# CBASS_RT_CFG0_ISC register map
Vendor: Texas Instruments
Peripheral module from a debugger description file (folder J722S).
Registers are 32-bit, read-write, reset 0x0 unless marked. A register's access mark holds for its fields unless they carry their own. Offsets are as the file gives them; lines under a group give offsets from that group; [hi:lo] are bit positions; {n}, {i} and the like mark numbered series; 'fields as' and 'values as' point back to an identical list; <NAME> marks a mode.

## CBASS_RT_CFG0_ISC
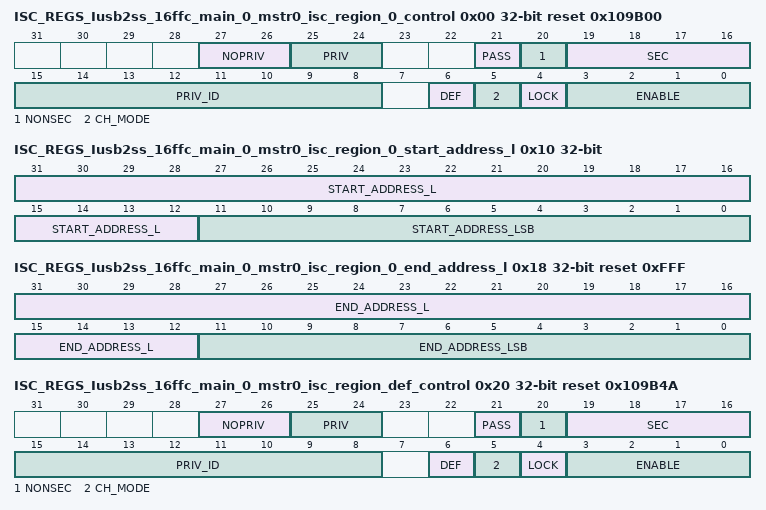
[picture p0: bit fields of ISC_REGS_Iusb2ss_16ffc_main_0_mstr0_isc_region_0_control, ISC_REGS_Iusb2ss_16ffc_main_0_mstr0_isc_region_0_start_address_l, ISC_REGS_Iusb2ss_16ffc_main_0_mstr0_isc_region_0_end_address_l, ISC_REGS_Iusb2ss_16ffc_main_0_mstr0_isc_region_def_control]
0x00 ISC_REGS_Iusb2ss_16ffc_main_0_mstr0_isc_region_0_control access not given reset 0x109B00 — The ISC Region 0 Control Register defines the control fields for the initiator Iusb2ss_16ffc_main_0.mstr0 region 0 ISC.
  [27:26] NOPRIV rw — Clear output priv attribute. If each bit is set then the outgoing priv bit is cleared.
  [25:24] PRIV rw — Set outgoing priv attribute. If each bit is set then the outgoing priv bit is set.
  [21] PASS rw — No privID replacement, pass through value.
  [20] NONSEC rw — Make outgoing non-secure.
  [19:16] SEC rw — Make outgoing secure. A value of 0xA enables, others disable.
  [15:8] PRIV_ID rw
  [6] DEF ro — Default region indication. The default region is used when all other regions do not match.
  [5] CH_MODE rw — Enable channel mode to match region to a chanid value. Otherwise use address mode to match region to an address range.
  [4] LOCK — Lock region. Once set the region values cannot be modified. (access R/W1TS)
  [3:0] ENABLE rw — Enable region. A value of 0xA enables, others disable.
0x10 ISC_REGS_Iusb2ss_16ffc_main_0_mstr0_isc_region_0_start_address_l — The ISC Region 0 Start Address Low Register defines the start address bits 31 to 0 for the initiator Iusb2ss_16ffc_main_0.mstr0 region 0 ISC.
  [31:12] START_ADDRESS_L — Start address bits 31 to 12.
  [11:0] START_ADDRESS_LSB — Start address bits 11 to 0 must be 0 as address must be 4KB aligned in address mode. Can also be channel number in channel mode.
0x14 ISC_REGS_Iusb2ss_16ffc_main_0_mstr0_isc_region_0_start_address_h — The ISC Region 0 Start Address High Register defines the start address bits 47 to 32 for the initiator Iusb2ss_16ffc_main_0.mstr0 region 0 ISC.
  [15:0] START_ADDRESS_H — Start address bits 47 to 32.
0x18 ISC_REGS_Iusb2ss_16ffc_main_0_mstr0_isc_region_0_end_address_l access per field reset 0xFFF — The ISC Region 0 End Address Low Register defines the end included address bits 31 to 0 for the initiator Iusb2ss_16ffc_main_0.mstr0 region 0 ISC.
  [31:12] END_ADDRESS_L rw — End address bits 31 to 12 to include in the match.
  [11:0] END_ADDRESS_LSB ro — End address bits 11 to 0 are forced to Fs as address must be 4KB aligned.
0x1C ISC_REGS_Iusb2ss_16ffc_main_0_mstr0_isc_region_0_end_address_h — The ISC Region 0 End Address High Register defines the end address bits 47 to 32 for the initiator Iusb2ss_16ffc_main_0.mstr0 region 0 ISC.
  [15:0] END_ADDRESS_H — End address bits 47 to 32.
0x20 ISC_REGS_Iusb2ss_16ffc_main_0_mstr0_isc_region_def_control access not given reset 0x109B4A — The ISC Default Region Control Register defines the control fields for the initiator Iusb2ss_16ffc_main_0.mstr0 region 1 ISC.
  [27:26] NOPRIV rw — Clear output priv attribute. If each bit is set then the outgoing priv bit is cleared, else the bit is unchanged. Do not set both priv and nopriv for the same bit.
  [25:24] PRIV rw — Set outgoing priv attribute. If each bit is set then the outgoing priv bit is set, else the bit is unchanged. Do not set both priv and nopriv for the same bit.
  [21] PASS rw — No privID replacement. A value of 1 will pass through privid value. A value of 0 will replace privid with priv_id field value.
  [20] NONSEC rw — Make outgoing non-secure. A value of 1 forces secure clear, others do nothing. Do not set both sec and nonsec.
  [19:16] SEC rw — Make outgoing secure. A value of 0xA forces secure set, others do nothing. Do not set both sec and nonsec.
  [15:8] PRIV_ID rw — Priv ID value to use if pass is 0.
  [6] DEF ro — Default region indication. The default region is used when all other regions do not match.
  [5] CH_MODE ro — Enable channel mode to match region to a chanid value. Otherwise use address mode to match region to an address range.
  [4] LOCK — Lock region. Once set, the region values cannot be modified. (access R/W1TS)
  [3:0] ENABLE ro — Enable region. A value of 0xA enables, others disable.
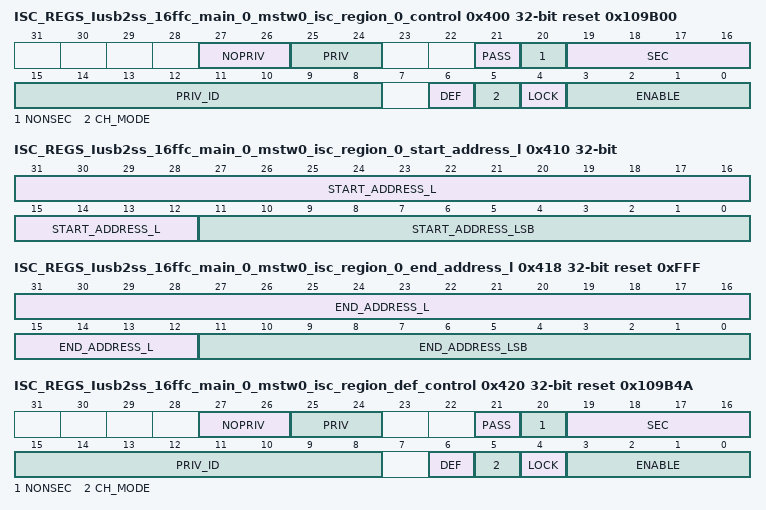
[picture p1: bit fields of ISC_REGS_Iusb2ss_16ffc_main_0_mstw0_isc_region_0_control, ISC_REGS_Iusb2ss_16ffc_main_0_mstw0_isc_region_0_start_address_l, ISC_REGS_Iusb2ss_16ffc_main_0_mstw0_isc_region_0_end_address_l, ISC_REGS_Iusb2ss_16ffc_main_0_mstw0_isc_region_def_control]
0x400 ISC_REGS_Iusb2ss_16ffc_main_0_mstw0_isc_region_0_control access not given reset 0x109B00 — The ISC Region 0 Control Register defines the control fields for the initiator Iusb2ss_16ffc_main_0.mstw0 region 0 ISC.
  fields as ISC_REGS_Iusb2ss_16ffc_main_0_mstr0_isc_region_0_control
0x410 ISC_REGS_Iusb2ss_16ffc_main_0_mstw0_isc_region_0_start_address_l — The ISC Region 0 Start Address Low Register defines the start address bits 31 to 0 for the initiator Iusb2ss_16ffc_main_0.mstw0 region 0 ISC.
  fields as ISC_REGS_Iusb2ss_16ffc_main_0_mstr0_isc_region_0_start_address_l
0x414 ISC_REGS_Iusb2ss_16ffc_main_0_mstw0_isc_region_0_start_address_h — The ISC Region 0 Start Address High Register defines the start address bits 47 to 32 for the initiator Iusb2ss_16ffc_main_0.mstw0 region 0 ISC.
  [15:0] START_ADDRESS_H — Start address bits 47 to 32.
0x418 ISC_REGS_Iusb2ss_16ffc_main_0_mstw0_isc_region_0_end_address_l access per field reset 0xFFF — The ISC Region 0 End Address Low Register defines the end included address bits 31 to 0 for the initiator Iusb2ss_16ffc_main_0.mstw0 region 0 ISC.
  fields as ISC_REGS_Iusb2ss_16ffc_main_0_mstr0_isc_region_0_end_address_l
0x41C ISC_REGS_Iusb2ss_16ffc_main_0_mstw0_isc_region_0_end_address_h — The ISC Region 0 End Address High Register defines the end address bits 47 to 32 for the initiator Iusb2ss_16ffc_main_0.mstw0 region 0 ISC.
  [15:0] END_ADDRESS_H — End address bits 47 to 32.
0x420 ISC_REGS_Iusb2ss_16ffc_main_0_mstw0_isc_region_def_control access not given reset 0x109B4A — The ISC Default Region Control Register defines the control fields for the initiator Iusb2ss_16ffc_main_0.mstw0 region 1 ISC.
  fields as ISC_REGS_Iusb2ss_16ffc_main_0_mstr0_isc_region_def_control
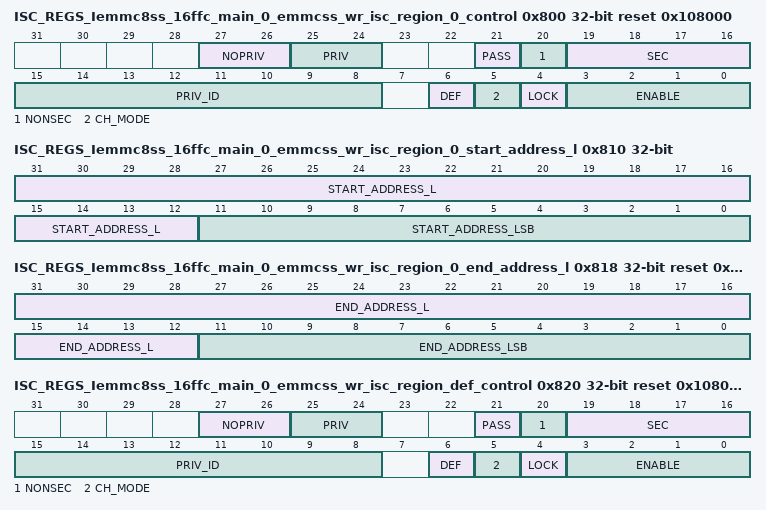
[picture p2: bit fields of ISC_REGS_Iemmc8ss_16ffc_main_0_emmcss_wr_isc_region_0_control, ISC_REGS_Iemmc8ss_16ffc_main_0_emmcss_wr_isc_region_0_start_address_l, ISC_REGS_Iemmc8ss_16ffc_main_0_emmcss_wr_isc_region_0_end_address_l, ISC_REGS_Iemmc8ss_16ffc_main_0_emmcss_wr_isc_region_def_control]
0x800 ISC_REGS_Iemmc8ss_16ffc_main_0_emmcss_wr_isc_region_0_control access not given reset 0x108000 — The ISC Region 0 Control Register defines the control fields for the initiator Iemmc8ss_16ffc_main_0.emmcss_wr region 0 ISC.
  fields as ISC_REGS_Iusb2ss_16ffc_main_0_mstr0_isc_region_0_control
0x810 ISC_REGS_Iemmc8ss_16ffc_main_0_emmcss_wr_isc_region_0_start_address_l — The ISC Region 0 Start Address Low Register defines the start address bits 31 to 0 for the initiator Iemmc8ss_16ffc_main_0.emmcss_wr region 0 ISC.
  fields as ISC_REGS_Iusb2ss_16ffc_main_0_mstr0_isc_region_0_start_address_l
0x814 ISC_REGS_Iemmc8ss_16ffc_main_0_emmcss_wr_isc_region_0_start_address_h — The ISC Region 0 Start Address High Register defines the start address bits 47 to 32 for the initiator Iemmc8ss_16ffc_main_0.emmcss_wr region 0 ISC.
  [15:0] START_ADDRESS_H — Start address bits 47 to 32.
0x818 ISC_REGS_Iemmc8ss_16ffc_main_0_emmcss_wr_isc_region_0_end_address_l access per field reset 0xFFF — The ISC Region 0 End Address Low Register defines the end included address bits 31 to 0 for the initiator Iemmc8ss_16ffc_main_0.emmcss_wr region 0 ISC.
  fields as ISC_REGS_Iusb2ss_16ffc_main_0_mstr0_isc_region_0_end_address_l
0x81C ISC_REGS_Iemmc8ss_16ffc_main_0_emmcss_wr_isc_region_0_end_address_h — The ISC Region 0 End Address High Register defines the end address bits 47 to 32 for the initiator Iemmc8ss_16ffc_main_0.emmcss_wr region 0 ISC.
  [15:0] END_ADDRESS_H — End address bits 47 to 32.
0x820 ISC_REGS_Iemmc8ss_16ffc_main_0_emmcss_wr_isc_region_def_control access not given reset 0x10804A — The ISC Default Region Control Register defines the control fields for the initiator Iemmc8ss_16ffc_main_0.emmcss_wr region 1 ISC.
  fields as ISC_REGS_Iusb2ss_16ffc_main_0_mstr0_isc_region_def_control
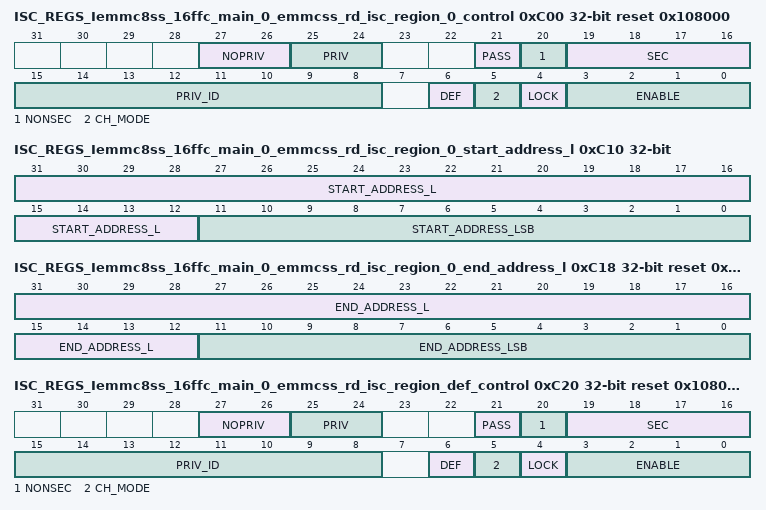
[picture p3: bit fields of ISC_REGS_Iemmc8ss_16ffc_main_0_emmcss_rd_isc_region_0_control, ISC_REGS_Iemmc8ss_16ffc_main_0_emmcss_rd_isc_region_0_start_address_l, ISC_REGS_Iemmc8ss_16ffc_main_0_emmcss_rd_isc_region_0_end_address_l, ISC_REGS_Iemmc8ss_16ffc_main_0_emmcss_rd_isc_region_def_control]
0xC00 ISC_REGS_Iemmc8ss_16ffc_main_0_emmcss_rd_isc_region_0_control access not given reset 0x108000 — The ISC Region 0 Control Register defines the control fields for the initiator Iemmc8ss_16ffc_main_0.emmcss_rd region 0 ISC.
  fields as ISC_REGS_Iusb2ss_16ffc_main_0_mstr0_isc_region_0_control
0xC10 ISC_REGS_Iemmc8ss_16ffc_main_0_emmcss_rd_isc_region_0_start_address_l — The ISC Region 0 Start Address Low Register defines the start address bits 31 to 0 for the initiator Iemmc8ss_16ffc_main_0.emmcss_rd region 0 ISC.
  fields as ISC_REGS_Iusb2ss_16ffc_main_0_mstr0_isc_region_0_start_address_l
0xC14 ISC_REGS_Iemmc8ss_16ffc_main_0_emmcss_rd_isc_region_0_start_address_h — The ISC Region 0 Start Address High Register defines the start address bits 47 to 32 for the initiator Iemmc8ss_16ffc_main_0.emmcss_rd region 0 ISC.
  [15:0] START_ADDRESS_H — Start address bits 47 to 32.
0xC18 ISC_REGS_Iemmc8ss_16ffc_main_0_emmcss_rd_isc_region_0_end_address_l access per field reset 0xFFF — The ISC Region 0 End Address Low Register defines the end included address bits 31 to 0 for the initiator Iemmc8ss_16ffc_main_0.emmcss_rd region 0 ISC.
  fields as ISC_REGS_Iusb2ss_16ffc_main_0_mstr0_isc_region_0_end_address_l
0xC1C ISC_REGS_Iemmc8ss_16ffc_main_0_emmcss_rd_isc_region_0_end_address_h — The ISC Region 0 End Address High Register defines the end address bits 47 to 32 for the initiator Iemmc8ss_16ffc_main_0.emmcss_rd region 0 ISC.
  [15:0] END_ADDRESS_H — End address bits 47 to 32.
0xC20 ISC_REGS_Iemmc8ss_16ffc_main_0_emmcss_rd_isc_region_def_control access not given reset 0x10804A — The ISC Default Region Control Register defines the control fields for the initiator Iemmc8ss_16ffc_main_0.emmcss_rd region 1 ISC.
  fields as ISC_REGS_Iusb2ss_16ffc_main_0_mstr0_isc_region_def_control
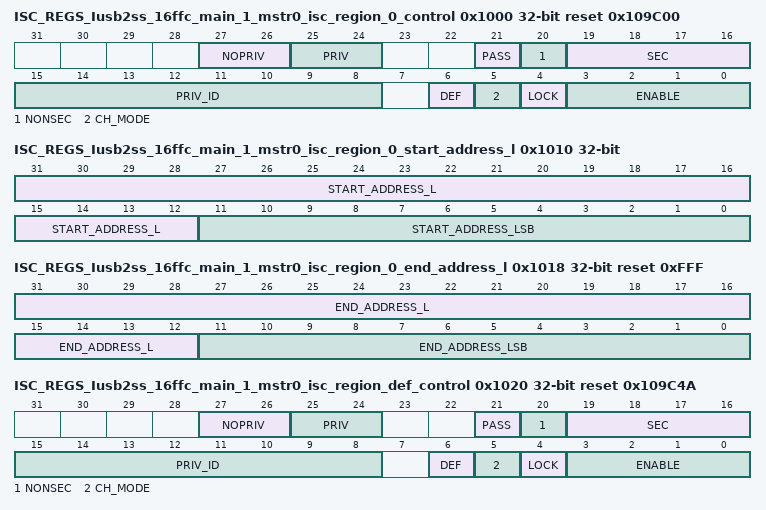
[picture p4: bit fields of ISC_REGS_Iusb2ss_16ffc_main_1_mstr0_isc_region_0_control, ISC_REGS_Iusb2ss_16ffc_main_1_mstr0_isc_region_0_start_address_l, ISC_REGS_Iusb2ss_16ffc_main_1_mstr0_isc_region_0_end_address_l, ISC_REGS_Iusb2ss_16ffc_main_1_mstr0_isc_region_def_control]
0x1000 ISC_REGS_Iusb2ss_16ffc_main_1_mstr0_isc_region_0_control access not given reset 0x109C00 — The ISC Region 0 Control Register defines the control fields for the initiator Iusb2ss_16ffc_main_1.mstr0 region 0 ISC.
  fields as ISC_REGS_Iusb2ss_16ffc_main_0_mstr0_isc_region_0_control
0x1010 ISC_REGS_Iusb2ss_16ffc_main_1_mstr0_isc_region_0_start_address_l — The ISC Region 0 Start Address Low Register defines the start address bits 31 to 0 for the initiator Iusb2ss_16ffc_main_1.mstr0 region 0 ISC.
  fields as ISC_REGS_Iusb2ss_16ffc_main_0_mstr0_isc_region_0_start_address_l
0x1014 ISC_REGS_Iusb2ss_16ffc_main_1_mstr0_isc_region_0_start_address_h — The ISC Region 0 Start Address High Register defines the start address bits 47 to 32 for the initiator Iusb2ss_16ffc_main_1.mstr0 region 0 ISC.
  [15:0] START_ADDRESS_H — Start address bits 47 to 32.
0x1018 ISC_REGS_Iusb2ss_16ffc_main_1_mstr0_isc_region_0_end_address_l access per field reset 0xFFF — The ISC Region 0 End Address Low Register defines the end included address bits 31 to 0 for the initiator Iusb2ss_16ffc_main_1.mstr0 region 0 ISC.
  fields as ISC_REGS_Iusb2ss_16ffc_main_0_mstr0_isc_region_0_end_address_l
0x101C ISC_REGS_Iusb2ss_16ffc_main_1_mstr0_isc_region_0_end_address_h — The ISC Region 0 End Address High Register defines the end address bits 47 to 32 for the initiator Iusb2ss_16ffc_main_1.mstr0 region 0 ISC.
  [15:0] END_ADDRESS_H — End address bits 47 to 32.
0x1020 ISC_REGS_Iusb2ss_16ffc_main_1_mstr0_isc_region_def_control access not given reset 0x109C4A — The ISC Default Region Control Register defines the control fields for the initiator Iusb2ss_16ffc_main_1.mstr0 region 1 ISC.
  fields as ISC_REGS_Iusb2ss_16ffc_main_0_mstr0_isc_region_def_control
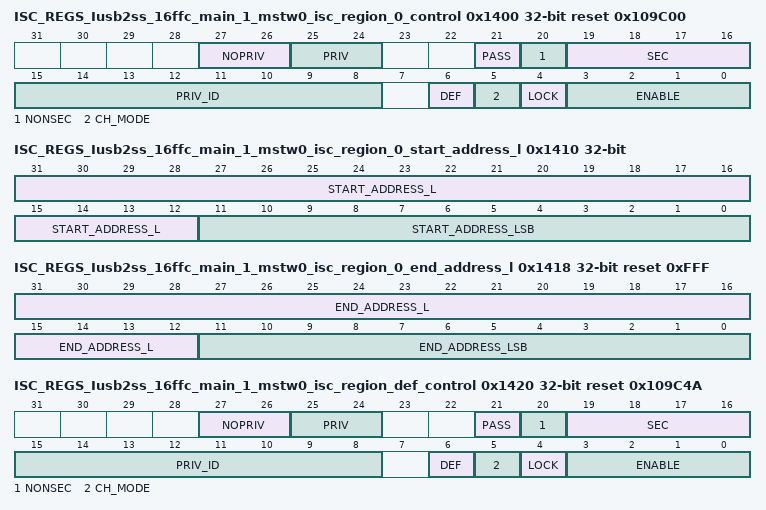
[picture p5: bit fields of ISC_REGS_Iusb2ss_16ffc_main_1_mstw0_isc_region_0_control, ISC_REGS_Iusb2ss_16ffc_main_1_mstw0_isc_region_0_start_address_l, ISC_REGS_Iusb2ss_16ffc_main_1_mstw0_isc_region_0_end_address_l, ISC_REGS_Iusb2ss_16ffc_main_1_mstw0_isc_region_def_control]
0x1400 ISC_REGS_Iusb2ss_16ffc_main_1_mstw0_isc_region_0_control access not given reset 0x109C00 — The ISC Region 0 Control Register defines the control fields for the initiator Iusb2ss_16ffc_main_1.mstw0 region 0 ISC.
  fields as ISC_REGS_Iusb2ss_16ffc_main_0_mstr0_isc_region_0_control
0x1410 ISC_REGS_Iusb2ss_16ffc_main_1_mstw0_isc_region_0_start_address_l — The ISC Region 0 Start Address Low Register defines the start address bits 31 to 0 for the initiator Iusb2ss_16ffc_main_1.mstw0 region 0 ISC.
  fields as ISC_REGS_Iusb2ss_16ffc_main_0_mstr0_isc_region_0_start_address_l
0x1414 ISC_REGS_Iusb2ss_16ffc_main_1_mstw0_isc_region_0_start_address_h — The ISC Region 0 Start Address High Register defines the start address bits 47 to 32 for the initiator Iusb2ss_16ffc_main_1.mstw0 region 0 ISC.
  [15:0] START_ADDRESS_H — Start address bits 47 to 32.
0x1418 ISC_REGS_Iusb2ss_16ffc_main_1_mstw0_isc_region_0_end_address_l access per field reset 0xFFF — The ISC Region 0 End Address Low Register defines the end included address bits 31 to 0 for the initiator Iusb2ss_16ffc_main_1.mstw0 region 0 ISC.
  fields as ISC_REGS_Iusb2ss_16ffc_main_0_mstr0_isc_region_0_end_address_l
0x141C ISC_REGS_Iusb2ss_16ffc_main_1_mstw0_isc_region_0_end_address_h — The ISC Region 0 End Address High Register defines the end address bits 47 to 32 for the initiator Iusb2ss_16ffc_main_1.mstw0 region 0 ISC.
  [15:0] END_ADDRESS_H — End address bits 47 to 32.
0x1420 ISC_REGS_Iusb2ss_16ffc_main_1_mstw0_isc_region_def_control access not given reset 0x109C4A — The ISC Default Region Control Register defines the control fields for the initiator Iusb2ss_16ffc_main_1.mstw0 region 1 ISC.
  fields as ISC_REGS_Iusb2ss_16ffc_main_0_mstr0_isc_region_def_control
